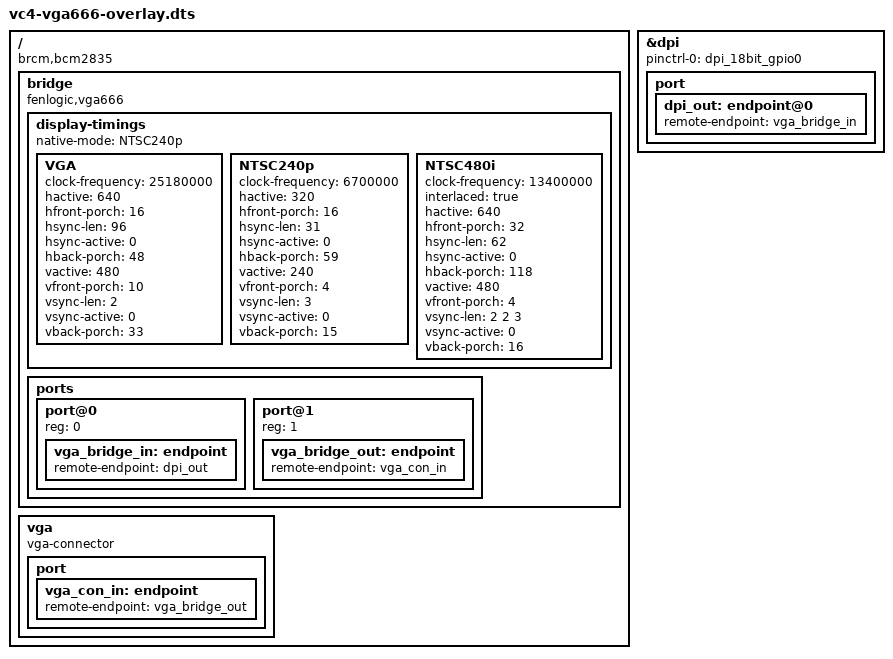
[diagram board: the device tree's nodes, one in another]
/dts-v1/;
/plugin/;

#include <dt-bindings/pinctrl/bcm2835.h>

/ {
	compatible = "brcm,bcm2835", "brcm,bcm2708", "brcm,bcm2709";

	fragment@0 {
		target-path = "/";
		__overlay__ {
			bridge: bridge {
				compatible = "fenlogic,vga666";
				#address-cells = <1>;
				#size-cells = <0>;

				display-timings {
					native-mode = <&NTSC240p>;
					VGA {
						clock-frequency = <25180000>;
						hactive = <640>;
						hfront-porch = <16>;
						hsync-len = <96>;
						hsync-active = <0>;
						hback-porch = <48>;
						vactive = <480>;
						vfront-porch = <10>;
						vsync-len = <2>;
						vsync-active = <0>;
						vback-porch = <33>;
					};

					NTSC240p {
						clock-frequency = <6700000>;
						hactive = <320>;
						hfront-porch = <16>;
						hsync-len = <31>;
						hsync-active = <0>;
						hback-porch = <59>;
						vactive = <240>;
						vfront-porch = <4>;
						vsync-len = <3>;
						vsync-active = <0>;
						vback-porch = <15>;
					}

					NTSC480i {
						clock-frequency = <13400000>;
						interlaced = <true>;
						hactive = <640>;
						hfront-porch = <32>;
						hsync-len = <62>;
						hsync-active = <0>;
						hback-porch = <118>;
						vactive = <480>;
						vfront-porch = <4>;
						vsync-len = <2 2 3>;
						vsync-active = <0>;
						vback-porch = <16>;
					}
				};

				ports {
					#address-cells = <1>;
					#size-cells = <0>;

					port@0 {
						reg = <0>;

						vga_bridge_in: endpoint {
							remote-endpoint = <&dpi_out>;
						};
					};

					port@1 {
						reg = <1>;

						vga_bridge_out: endpoint {
							remote-endpoint = <&vga_con_in>;
						};
					};
				};
			};

			vga {
				compatible = "vga-connector";

				port {
					vga_con_in: endpoint {
						remote-endpoint = <&vga_bridge_out>;
					};
				};
			};
		};
	};

	fragment@1 {
		target = <&dpi>;
		__overlay__  {
			status = "okay";

			pinctrl-names = "default";
			pinctrl-0 = <&dpi_18bit_gpio0>;

			port {
				dpi_out: endpoint@0 {
					remote-endpoint = <&vga_bridge_in>;
				};
			};
		};
	};
};
